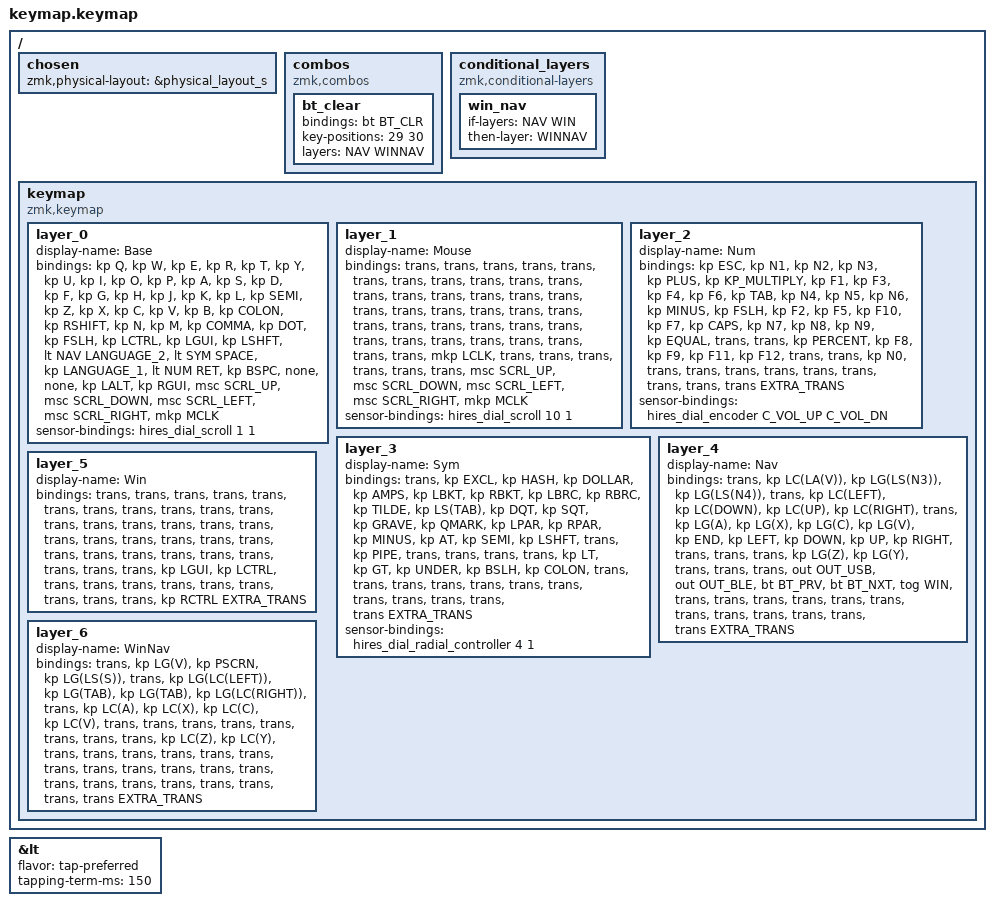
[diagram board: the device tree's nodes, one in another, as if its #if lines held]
#include <behaviors.dtsi>
#include <dt-bindings/zmk/bt.h>
#include <dt-bindings/zmk/keys.h>
#include <dt-bindings/zmk/outputs.h>
#include <dt-bindings/zmk/pointing.h>

#if defined(TORABO_TSUKI_LP_INPUT_HIRES_DIAL)
#include <behaviors/hires_dial.dtsi>
#endif

#define BASE   0
#define MOUSE  1
#define NUM    2
#define SYM    3
#define NAV    4
#define WIN    5
#define WINNAV 6

/* Decide hold by time only, with a shorter tapping-term than the default 200ms. */
&lt {
    flavor = "tap-preferred";
    tapping-term-ms = <150>;
};

#if defined(TORABO_TSUKI_LP_KSCAN_4_DIRECTION_SWITCH)
#define EXTRA_TRANS &trans &trans &trans &trans &trans
#elif defined(TORABO_TSUKI_LP_INPUT_HIRES_DIAL)
#define EXTRA_TRANS &trans
#else
#define EXTRA_TRANS
#endif

/ {
    chosen {
        zmk,physical-layout = &physical_layout_s;
    };

    combos {
        compatible = "zmk,combos";

        /* BT_PRV + BT_NXT on the NAV layer */
        bt_clear {
            bindings = <&bt BT_CLR>;
            key-positions = <29 30>;
            layers = <NAV WINNAV>;
        };
    };

    /* Windows shortcuts are active only while both NAV and WIN are active. */
    conditional_layers {
        compatible = "zmk,conditional-layers";

        win_nav {
            if-layers = <NAV WIN>;
            then-layer = <WINNAV>;
        };
    };

    keymap {
        compatible = "zmk,keymap";

        layer_0 {
            display-name = "Base";
            bindings = <
&kp Q      &kp W     &kp E      &kp R              &kp T                                                            &kp Y        &kp U     &kp I      &kp O     &kp P
&kp A      &kp S     &kp D      &kp F              &kp G                                                            &kp H        &kp J     &kp K      &kp L     &kp SEMI
&kp Z      &kp X     &kp C      &kp V              &kp B              &kp COLON                    &kp RSHIFT       &kp N        &kp M     &kp COMMA  &kp DOT   &kp FSLH
&kp LCTRL  &kp LGUI  &kp LSHFT  &lt NAV LANGUAGE_2  &lt SYM SPACE      &kp LANGUAGE_1               &lt NUM RET      &kp BSPC     &none     &none      &kp LALT  &kp RGUI
#if defined(TORABO_TSUKI_LP_KSCAN_4_DIRECTION_SWITCH)
&msc SCRL_UP &msc SCRL_DOWN &msc SCRL_LEFT &msc SCRL_RIGHT &mkp MCLK
#elif defined(TORABO_TSUKI_LP_INPUT_HIRES_DIAL)
&mkp MCLK
#endif
            >;
        };

        layer_1 {
            display-name = "Mouse";
            bindings = <
&trans  &trans  &trans  &trans  &trans                      &trans  &trans  &trans  &trans  &trans
&trans  &trans  &trans  &trans  &trans                      &trans  &trans  &trans  &trans  &trans
&trans  &trans  &trans  &trans  &trans  &trans      &trans  &trans  &trans  &trans  &trans  &trans
&trans  &trans  &trans  &trans  &trans  &mkp LCLK   &trans  &trans  &trans  &trans  &trans  &trans
#if defined(TORABO_TSUKI_LP_KSCAN_4_DIRECTION_SWITCH)
&msc SCRL_UP &msc SCRL_DOWN &msc SCRL_LEFT &msc SCRL_RIGHT &mkp MCLK
#elif defined(TORABO_TSUKI_LP_INPUT_HIRES_DIAL)
&mkp MCLK
#endif
            >;
        };

        layer_2 {
            display-name = "Num";
            bindings = <
&kp ESC   &kp N1  &kp N2  &kp N3  &kp PLUS                            &kp KP_MULTIPLY  &kp F1  &kp F3   &kp F4   &kp F6
&kp TAB   &kp N4  &kp N5  &kp N6  &kp MINUS                           &kp FSLH         &kp F2  &kp F5   &kp F10  &kp F7
&kp CAPS  &kp N7  &kp N8  &kp N9  &kp EQUAL  &trans           &trans  &kp PERCENT      &kp F8  &kp F9   &kp F11  &kp F12
&trans    &trans  &kp N0  &trans  &trans     &trans           &trans  &trans           &trans  &trans   &trans   &trans
EXTRA_TRANS
            >;
        };

        layer_3 {
            display-name = "Sym";
            bindings = <
&trans       &kp EXCL  &kp HASH  &kp DOLLAR  &kp AMPS                      &kp LBKT  &kp RBKT  &kp LBRC   &kp RBRC  &kp TILDE
&kp LS(TAB)  &kp DQT   &kp SQT   &kp GRAVE   &kp QMARK                      &kp LPAR  &kp RPAR  &kp MINUS  &kp AT    &kp SEMI
&kp LSHFT    &trans    &kp PIPE  &trans      &trans     &trans      &trans  &kp LT    &kp GT    &kp UNDER  &kp BSLH  &kp COLON
&trans       &trans    &trans    &trans      &trans     &trans      &trans  &trans    &trans    &trans     &trans    &trans
EXTRA_TRANS
            >;
        };

        layer_4 {
            display-name = "Nav";
            bindings = <
&trans     &kp LC(LA(V))  &kp LG(LS(N3))  &kp LG(LS(N4))  &trans                               &kp LC(LEFT)  &kp LC(DOWN)  &kp LC(UP)   &kp LC(RIGHT)  &trans
&kp LG(A)  &kp LG(X)      &kp LG(C)       &kp LG(V)       &kp END                              &kp LEFT      &kp DOWN      &kp UP       &kp RIGHT      &trans
&trans     &trans         &kp LG(Z)       &kp LG(Y)       &trans   &trans             &trans   &out OUT_USB  &out OUT_BLE  &bt BT_PRV   &bt BT_NXT     &tog WIN
&trans     &trans         &trans          &trans          &trans   &trans             &trans   &trans        &trans        &trans       &trans         &trans
EXTRA_TRANS
            >;
        };

        /* Toggled by &tog WIN. Swaps Mac modifiers for Windows ones; everything else falls through. */
        layer_5 {
            display-name = "Win";
            bindings = <
&trans    &trans     &trans  &trans  &trans                      &trans  &trans  &trans  &trans  &trans
&trans    &trans     &trans  &trans  &trans                      &trans  &trans  &trans  &trans  &trans
&trans    &trans     &trans  &trans  &trans  &trans      &trans  &trans  &trans  &trans  &trans  &trans
&kp LGUI  &kp LCTRL  &trans  &trans  &trans  &trans      &trans  &trans  &trans  &trans  &trans  &kp RCTRL
EXTRA_TRANS
            >;
        };

        /* Windows equivalents of the NAV layer shortcuts (activated by conditional_layers). */
        layer_6 {
            display-name = "WinNav";
            bindings = <
&trans     &kp LG(V)  &kp PSCRN  &kp LG(LS(S))  &trans                     &kp LG(LC(LEFT))  &kp LG(TAB)  &kp LG(TAB)  &kp LG(LC(RIGHT))  &trans
&kp LC(A)  &kp LC(X)  &kp LC(C)  &kp LC(V)      &trans                     &trans            &trans       &trans       &trans             &trans
&trans     &trans     &kp LC(Z)  &kp LC(Y)      &trans  &trans     &trans  &trans            &trans       &trans       &trans             &trans
&trans     &trans     &trans     &trans         &trans  &trans     &trans  &trans            &trans       &trans       &trans             &trans
EXTRA_TRANS
            >;
        };
    };
};

#if defined(TORABO_TSUKI_LP_INPUT_HIRES_DIAL)
&{/keymap/layer_0} {
    sensor-bindings = <&hires_dial_scroll 1 1>;
};

&{/keymap/layer_1} {
    sensor-bindings = <&hires_dial_scroll 10 1>;
};

&{/keymap/layer_2} {
    sensor-bindings = <&hires_dial_encoder C_VOL_UP C_VOL_DN>;
};

&{/keymap/layer_3} {
    /* Quarter-speed Radial Controller motion: output/input = 1/4. */
    sensor-bindings = <&hires_dial_radial_controller 4 1>;
};
#endif
